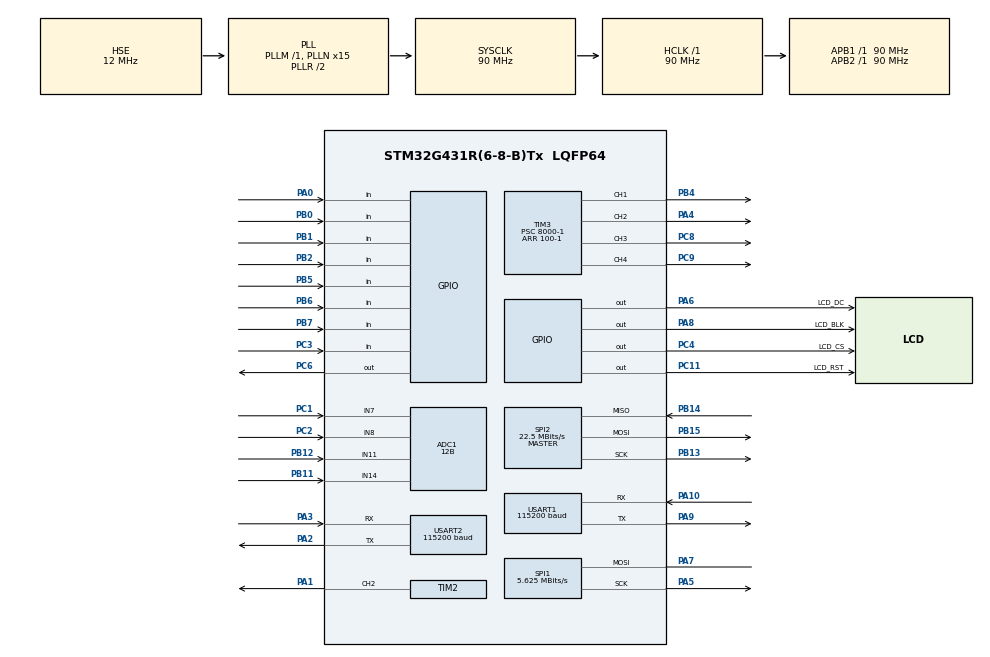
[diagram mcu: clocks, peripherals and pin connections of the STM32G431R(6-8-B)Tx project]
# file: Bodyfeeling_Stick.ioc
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ADC1.Channel-0\#ChannelRegularConversion=ADC_CHANNEL_11
ADC1.Channel-1\#ChannelRegularConversion=ADC_CHANNEL_7
ADC1.Channel-2\#ChannelRegularConversion=ADC_CHANNEL_8
ADC1.Channel-3\#ChannelRegularConversion=ADC_CHANNEL_14
ADC1.ClockPrescaler=ADC_CLOCK_ASYNC_DIV4
ADC1.ContinuousConvMode=ENABLE
ADC1.DMAContinuousRequests=ENABLE
ADC1.EOCSelection=ADC_EOC_SINGLE_CONV
ADC1.NbrOfConversion=4
ADC1.NbrOfConversionFlag=1
ADC1.OffsetNumber-0\#ChannelRegularConversion=ADC_OFFSET_NONE
ADC1.OffsetNumber-1\#ChannelRegularConversion=ADC_OFFSET_NONE
ADC1.OffsetNumber-2\#ChannelRegularConversion=ADC_OFFSET_NONE
ADC1.OffsetNumber-3\#ChannelRegularConversion=ADC_OFFSET_NONE
ADC1.Rank-0\#ChannelRegularConversion=1
ADC1.Rank-1\#ChannelRegularConversion=2
ADC1.Rank-2\#ChannelRegularConversion=3
ADC1.Rank-3\#ChannelRegularConversion=4
ADC1.Resolution=ADC_RESOLUTION_12B
ADC1.SamplingTime-0\#ChannelRegularConversion=ADC_SAMPLETIME_640CYCLES_5
ADC1.SamplingTime-1\#ChannelRegularConversion=ADC_SAMPLETIME_92CYCLES_5
ADC1.SamplingTime-2\#ChannelRegularConversion=ADC_SAMPLETIME_92CYCLES_5
ADC1.SamplingTime-3\#ChannelRegularConversion=ADC_SAMPLETIME_247CYCLES_5
ADC1.master=1
Dma.ADC1.0.Direction=DMA_PERIPH_TO_MEMORY
Dma.ADC1.0.EventEnable=DISABLE
Dma.ADC1.0.Instance=DMA1_Channel1
Dma.ADC1.0.MemDataAlignment=DMA_MDATAALIGN_HALFWORD
Dma.ADC1.0.MemInc=DMA_MINC_ENABLE
Dma.ADC1.0.Mode=DMA_CIRCULAR
Dma.ADC1.0.PeriphDataAlignment=DMA_PDATAALIGN_HALFWORD
Dma.ADC1.0.PeriphInc=DMA_PINC_DISABLE
Dma.ADC1.0.Polarity=HAL_DMAMUX_REQ_GEN_RISING
Dma.ADC1.0.Priority=DMA_PRIORITY_LOW
Dma.ADC1.0.RequestNumber=1
Dma.ADC1.0.SignalID=NONE
Dma.ADC1.0.SyncEnable=DISABLE
Dma.ADC1.0.SyncPolarity=HAL_DMAMUX_SYNC_NO_EVENT
Dma.ADC1.0.SyncRequestNumber=1
Dma.ADC1.0.SyncSignalID=NONE
Dma.Request0=ADC1
Dma.Request1=USART2_RX
Dma.Request2=USART1_TX
Dma.Request3=USART1_RX
Dma.Request4=USART2_TX
Dma.USART1_RX.3.Direction=DMA_PERIPH_TO_MEMORY
Dma.USART1_RX.3.EventEnable=DISABLE
Dma.USART1_RX.3.Instance=DMA1_Channel5
Dma.USART1_RX.3.MemDataAlignment=DMA_MDATAALIGN_BYTE
Dma.USART1_RX.3.MemInc=DMA_MINC_ENABLE
Dma.USART1_RX.3.Mode=DMA_NORMAL
Dma.USART1_RX.3.PeriphDataAlignment=DMA_PDATAALIGN_BYTE
Dma.USART1_RX.3.PeriphInc=DMA_PINC_DISABLE
Dma.USART1_RX.3.Polarity=HAL_DMAMUX_REQ_GEN_RISING
Dma.USART1_RX.3.Priority=DMA_PRIORITY_MEDIUM
Dma.USART1_RX.3.RequestNumber=1
Dma.USART1_RX.3.SignalID=NONE
Dma.USART1_RX.3.SyncEnable=DISABLE
Dma.USART1_RX.3.SyncPolarity=HAL_DMAMUX_SYNC_NO_EVENT
Dma.USART1_RX.3.SyncRequestNumber=1
Dma.USART1_RX.3.SyncSignalID=NONE
Dma.USART1_TX.2.Direction=DMA_MEMORY_TO_PERIPH
Dma.USART1_TX.2.EventEnable=DISABLE
Dma.USART1_TX.2.Instance=DMA1_Channel4
Dma.USART1_TX.2.MemDataAlignment=DMA_MDATAALIGN_BYTE
Dma.USART1_TX.2.MemInc=DMA_MINC_ENABLE
Dma.USART1_TX.2.Mode=DMA_CIRCULAR
Dma.USART1_TX.2.PeriphDataAlignment=DMA_PDATAALIGN_BYTE
Dma.USART1_TX.2.PeriphInc=DMA_PINC_DISABLE
Dma.USART1_TX.2.Polarity=HAL_DMAMUX_REQ_GEN_RISING
Dma.USART1_TX.2.Priority=DMA_PRIORITY_LOW
Dma.USART1_TX.2.RequestNumber=1
Dma.USART1_TX.2.SignalID=NONE
Dma.USART1_TX.2.SyncEnable=DISABLE
Dma.USART1_TX.2.SyncPolarity=HAL_DMAMUX_SYNC_NO_EVENT
Dma.USART1_TX.2.SyncRequestNumber=1
Dma.USART1_TX.2.SyncSignalID=NONE
Dma.USART2_RX.1.Direction=DMA_PERIPH_TO_MEMORY
Dma.USART2_RX.1.EventEnable=DISABLE
Dma.USART2_RX.1.Instance=DMA1_Channel6
Dma.USART2_RX.1.MemDataAlignment=DMA_MDATAALIGN_BYTE
Dma.USART2_RX.1.MemInc=DMA_MINC_ENABLE
Dma.USART2_RX.1.Mode=DMA_NORMAL
Dma.USART2_RX.1.PeriphDataAlignment=DMA_PDATAALIGN_BYTE
Dma.USART2_RX.1.PeriphInc=DMA_PINC_DISABLE
Dma.USART2_RX.1.Polarity=HAL_DMAMUX_REQ_GEN_RISING
Dma.USART2_RX.1.Priority=DMA_PRIORITY_MEDIUM
Dma.USART2_RX.1.RequestNumber=1
Dma.USART2_RX.1.SignalID=NONE
Dma.USART2_RX.1.SyncEnable=DISABLE
Dma.USART2_RX.1.SyncPolarity=HAL_DMAMUX_SYNC_NO_EVENT
Dma.USART2_RX.1.SyncRequestNumber=1
Dma.USART2_RX.1.SyncSignalID=NONE
Dma.USART2_TX.4.Direction=DMA_MEMORY_TO_PERIPH
Dma.USART2_TX.4.EventEnable=DISABLE
Dma.USART2_TX.4.Instance=DMA1_Channel2
Dma.USART2_TX.4.MemDataAlignment=DMA_MDATAALIGN_BYTE
Dma.USART2_TX.4.MemInc=DMA_MINC_ENABLE
Dma.USART2_TX.4.Mode=DMA_NORMAL
Dma.USART2_TX.4.PeriphDataAlignment=DMA_PDATAALIGN_BYTE
Dma.USART2_TX.4.PeriphInc=DMA_PINC_DISABLE
Dma.USART2_TX.4.Polarity=HAL_DMAMUX_REQ_GEN_RISING
Dma.USART2_TX.4.Priority=DMA_PRIORITY_LOW
Dma.USART2_TX.4.RequestNumber=1
Dma.USART2_TX.4.SignalID=NONE
Dma.USART2_TX.4.SyncEnable=DISABLE
Dma.USART2_TX.4.SyncPolarity=HAL_DMAMUX_SYNC_NO_EVENT
Dma.USART2_TX.4.SyncRequestNumber=1
Dma.USART2_TX.4.SyncSignalID=NONE
FREERTOS.BinarySemaphores01=myBinarySem01,Dynamic,NULL,Available
FREERTOS.Tasks01=defaultTask,0,128,StartDefaultTask,Default,NULL,Dynamic,NULL,NULL;LcdShow,-3,128,LcdShow_02,Default,NULL,Dynamic,NULL,NULL;Send_Rec_msg,-3,128,Send_Rec_msg_03,Default,NULL,Dynamic,NULL,NULL
Mcu.Family=STM32G4
Mcu.Name=STM32G431R(6-8-B)Tx
Mcu.Package=LQFP64
NVIC.DMA1_Channel1_IRQn=true\:5\:0\:false\:false\:true\:true\:false\:true\:true
NVIC.DMA1_Channel4_IRQn=true\:5\:0\:false\:false\:true\:false\:false\:true\:true
NVIC.DMA1_Channel5_IRQn=true\:5\:0\:false\:false\:true\:false\:false\:true\:true
NVIC.DMA1_Channel6_IRQn=true\:5\:0\:false\:false\:true\:false\:false\:true\:true
NVIC.PriorityGroup=NVIC_PRIORITYGROUP_4
NVIC.TIM6_DAC_IRQn=true\:15\:0\:false\:false\:true\:false\:false\:true\:true
NVIC.TIM7_IRQn=true\:5\:0\:false\:false\:true\:true\:true\:true\:true
NVIC.TimeBase=TIM6_DAC_IRQn
NVIC.TimeBaseIP=TIM6
NVIC.USART2_IRQn=true\:5\:0\:true\:false\:true\:true\:true\:true\:true
PA0.GPIO_Mode=GPIO_MODE_INPUT
PA0.GPIO_PuPd=GPIO_PULLUP
PA0.Signal=GPIO_Input
PA1.Signal=S_TIM2_CH2
PA10.GPIO_PuPd=GPIO_PULLDOWN
PA10.GPIO_Speed=GPIO_SPEED_FREQ_MEDIUM
PA10.Mode=Asynchronous
PA10.Signal=USART1_RX
PA13.Mode=Serial_Wire
PA13.Signal=SYS_JTMS-SWDIO
PA14.Mode=Serial_Wire
PA14.Signal=SYS_JTCK-SWCLK
PA2.Mode=Asynchronous
PA2.Signal=USART2_TX
PA3.Mode=Asynchronous
PA3.Signal=USART2_RX
PA4.Signal=S_TIM3_CH2
PA5.GPIO_PuPd=GPIO_PULLUP
PA5.GPIO_Speed=GPIO_SPEED_FREQ_HIGH
PA5.Mode=Simplex_Bidirectional_Master
PA5.Signal=SPI1_SCK
PA6.GPIO_Label=LCD_DC
PA6.Signal=GPIO_Output
PA7.GPIO_PuPd=GPIO_PULLUP
PA7.GPIO_Speed=GPIO_SPEED_FREQ_HIGH
PA7.Mode=Simplex_Bidirectional_Master
PA7.Signal=SPI1_MOSI
PA8.GPIO_Label=LCD_BLK
PA8.Signal=GPIO_Output
PA9.GPIO_PuPd=GPIO_PULLDOWN
PA9.GPIO_Speed=GPIO_SPEED_FREQ_MEDIUM
PA9.Mode=Asynchronous
PA9.Signal=USART1_TX
PB0.GPIO_Mode=GPIO_MODE_INPUT
PB0.GPIO_PuPd=GPIO_PULLUP
PB0.Signal=GPIO_Input
PB1.GPIO_Mode=GPIO_MODE_INPUT
PB1.GPIO_PuPd=GPIO_PULLUP
PB1.Signal=GPIO_Input
PB11.Signal=SharedAnalog_PB11
PB12.Signal=SharedAnalog_PB12
PB13.Mode=Full_Duplex_Master
PB13.Signal=SPI2_SCK
PB14.Mode=Full_Duplex_Master
PB14.Signal=SPI2_MISO
PB15.Mode=Full_Duplex_Master
PB15.Signal=SPI2_MOSI
PB2.GPIO_Mode=GPIO_MODE_INPUT
PB2.GPIO_PuPd=GPIO_PULLUP
PB2.Signal=GPIO_Input
PB4.Signal=S_TIM3_CH1
PB5.Signal=GPIO_Input
PB6.Signal=GPIO_Input
PB7.Signal=GPIO_Input
PC1.Signal=SharedAnalog_PC1
PC11.GPIO_Label=LCD_RST
PC11.Signal=GPIO_Output
PC2.Signal=SharedAnalog_PC2
PC3.GPIO_PuPd=GPIO_PULLUP
PC3.Signal=GPIO_Input
PC4.GPIO_Label=LCD_CS
PC4.Signal=GPIO_Output
PC6.Signal=GPIO_Output
PC8.Signal=S_TIM3_CH3
PC9.Signal=S_TIM3_CH4
PF0-OSC_IN.Mode=HSE-External-Oscillator
PF0-OSC_IN.Signal=RCC_OSC_IN
PF1-OSC_OUT.Mode=HSE-External-Oscillator
PF1-OSC_OUT.Signal=RCC_OSC_OUT
ProjectManager.HeapSize=0x200
ProjectManager.StackSize=0x400
ProjectManager.TargetToolchain=MDK-ARM V5.32
RCC.ADC12Freq_Value=90000000
RCC.AHBFreq_Value=90000000
RCC.APB1Freq_Value=90000000
RCC.APB1TimFreq_Value=90000000
RCC.APB2Freq_Value=90000000
RCC.APB2TimFreq_Value=90000000
RCC.CK48CLockSelection=RCC_USBCLKSOURCE_HSI48
RCC.CortexFreq_Value=90000000
RCC.EXTERNAL_CLOCK_VALUE=12288000
RCC.FLatency=FLASH_LATENCY_2
RCC.HCLKFreq_Value=90000000
RCC.HSE_VALUE=12000000
RCC.HSI48_VALUE=48000000
RCC.HSI_VALUE=16000000
RCC.LSE_VALUE=32768
RCC.PLLN=15
RCC.PLLSourceVirtual=RCC_PLLSOURCE_HSE
RCC.PWR_Regulator_Voltage_Scale=PWR_REGULATOR_VOLTAGE_SCALE1_BOOST
RCC.SYSCLKFreq_VALUE=90000000
RCC.SYSCLKSource=RCC_SYSCLKSOURCE_PLLCLK
RCC.USBFreq_Value=48000000
RCC.VCOOutputFreq_Value=180000000
SH.S_TIM2_CH2.0=TIM2_CH2,PWM Generation2 CH2
SH.S_TIM3_CH1.0=TIM3_CH1,PWM Generation1 CH1
SH.S_TIM3_CH2.0=TIM3_CH2,PWM Generation2 CH2
SH.S_TIM3_CH3.0=TIM3_CH3,PWM Generation3 CH3
SH.S_TIM3_CH4.0=TIM3_CH4,PWM Generation4 CH4
SH.SharedAnalog_PB11.0=GPIO_Analog
SH.SharedAnalog_PB11.1=ADC1_IN14,IN14-Single-Ended
SH.SharedAnalog_PB12.0=GPIO_Analog
SH.SharedAnalog_PB12.1=ADC1_IN11,IN11-Single-Ended
SH.SharedAnalog_PC1.0=GPIO_Analog
SH.SharedAnalog_PC1.1=ADC1_IN7,IN7-Single-Ended
SH.SharedAnalog_PC2.0=GPIO_Analog
SH.SharedAnalog_PC2.1=ADC1_IN8,IN8-Single-Ended
SPI1.BaudRatePrescaler=SPI_BAUDRATEPRESCALER_16
SPI1.CLKPhase=SPI_PHASE_2EDGE
SPI1.CLKPolarity=SPI_POLARITY_HIGH
SPI1.CRCCalculation=SPI_CRCCALCULATION_DISABLE
SPI1.CalculateBaudRate=5.625 MBits/s
SPI1.DataSize=SPI_DATASIZE_8BIT
SPI1.Direction=SPI_DIRECTION_1LINE
SPI1.FirstBit=SPI_FIRSTBIT_MSB
SPI1.Mode=SPI_MODE_MASTER
SPI1.NSS=SPI_NSS_SOFT
SPI1.TIMode=SPI_TIMODE_DISABLE
SPI1.VirtualType=VM_MASTER
SPI2.BaudRatePrescaler=SPI_BAUDRATEPRESCALER_4
SPI2.CLKPhase=SPI_PHASE_2EDGE
SPI2.CLKPolarity=SPI_POLARITY_HIGH
SPI2.CalculateBaudRate=22.5 MBits/s
SPI2.DataSize=SPI_DATASIZE_8BIT
SPI2.Direction=SPI_DIRECTION_2LINES
SPI2.Mode=SPI_MODE_MASTER
SPI2.VirtualType=VM_MASTER
TIM2.Channel-PWM\ Generation2\ CH2=TIM_CHANNEL_2
TIM3.Channel-PWM\ Generation1\ CH1=TIM_CHANNEL_1
TIM3.Channel-PWM\ Generation2\ CH2=TIM_CHANNEL_2
TIM3.Channel-PWM\ Generation3\ CH3=TIM_CHANNEL_3
TIM3.Channel-PWM\ Generation4\ CH4=TIM_CHANNEL_4
TIM3.PeriodNoDither=100-1
TIM3.Prescaler=8000-1
TIM7.PeriodNoDither=50-1
TIM7.Prescaler=9000-1
USART1.BaudRate=115200
USART1.VirtualMode-Asynchronous=VM_ASYNC
USART2.BaudRate=115200
USART2.VirtualMode-Asynchronous=VM_ASYNC
VP_FREERTOS_VS_CMSIS_V1.Mode=CMSIS_V1
VP_SYS_VS_DBSignals.Mode=DisableDeadBatterySignals
VP_SYS_VS_tim6.Mode=TIM6
VP_TIM7_VS_ClockSourceINT.Mode=Enable_Timer
board=custom

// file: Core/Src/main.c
/* USER CODE BEGIN Header */
/**
 ******************************************************************************
 * @file           : main.c
 * @brief          : Main program body
 ******************************************************************************
 * @attention
 *
 * Copyright (c) 2024 STMicroelectronics.
 * All rights reserved.
 *
 * This software is licensed under terms that can be found in the LICENSE file
 * in the root directory of this software component.
 * If no LICENSE file comes with this software, it is provided AS-IS.
 *
 ******************************************************************************
 */
/* USER CODE END Header */
#include "main.h"
#include "cmsis_os.h"
#include "adc.h"
#include "dma.h"
#include "spi.h"
#include "tim.h"
#include "usart.h"
#include "gpio.h"

/* USER CODE BEGIN Includes */
#include "HEAD.h"
/* USER CODE END Includes */

void SystemClock_Config(void);
void MX_FREERTOS_Init(void);

int main(void)
{

  /* MCU Configuration--------------------------------------------------------*/

  /* Reset of all peripherals, Initializes the Flash interface and the Systick. */
  HAL_Init();

  /* Configure the system clock */
  SystemClock_Config();

  /* Initialize all configured peripherals */
  MX_GPIO_Init();
  MX_DMA_Init();
  MX_SPI1_Init();
  MX_USART2_UART_Init();
  MX_USART1_UART_Init();
  MX_SPI2_Init();
  MX_ADC1_Init();
  MX_TIM3_Init();
  MX_TIM2_Init();
  MX_TIM7_Init();
  /* USER CODE BEGIN 2 */

    fun_init();

  /* USER CODE END 2 */

  /* Call init function for freertos objects (in cmsis_os2.c) */
  MX_FREERTOS_Init();

  /* Start scheduler */
  osKernelStart();

  /* We should never get here as control is now taken by the scheduler */

  /* Infinite loop */
    while (1)
    {

    /* USER CODE BEGIN 3 */
        fun_while();
    }
  /* USER CODE END 3 */
}

void SystemClock_Config(void)
{
  RCC_OscInitTypeDef RCC_OscInitStruct = {0};
  RCC_ClkInitTypeDef RCC_ClkInitStruct = {0};

  /** Configure the main internal regulator output voltage
  */
  HAL_PWREx_ControlVoltageScaling(PWR_REGULATOR_VOLTAGE_SCALE1_BOOST);

  /** Initializes the RCC Oscillators according to the specified parameters
  * in the RCC_OscInitTypeDef structure.
  */
  RCC_OscInitStruct.OscillatorType = RCC_OSCILLATORTYPE_HSE;
  RCC_OscInitStruct.HSEState = RCC_HSE_ON;
  RCC_OscInitStruct.PLL.PLLState = RCC_PLL_ON;
  RCC_OscInitStruct.PLL.PLLSource = RCC_PLLSOURCE_HSE;
  RCC_OscInitStruct.PLL.PLLM = RCC_PLLM_DIV1;
  RCC_OscInitStruct.PLL.PLLN = 15;
  RCC_OscInitStruct.PLL.PLLP = RCC_PLLP_DIV2;
  RCC_OscInitStruct.PLL.PLLQ = RCC_PLLQ_DIV2;
  RCC_OscInitStruct.PLL.PLLR = RCC_PLLR_DIV2;
  if (HAL_RCC_OscConfig(&RCC_OscInitStruct) != HAL_OK)
  {
    Error_Handler();
  }

  /** Initializes the CPU, AHB and APB buses clocks
  */
  RCC_ClkInitStruct.ClockType = RCC_CLOCKTYPE_HCLK|RCC_CLOCKTYPE_SYSCLK
                              |RCC_CLOCKTYPE_PCLK1|RCC_CLOCKTYPE_PCLK2;
  RCC_ClkInitStruct.SYSCLKSource = RCC_SYSCLKSOURCE_PLLCLK;
  RCC_ClkInitStruct.AHBCLKDivider = RCC_SYSCLK_DIV1;
  RCC_ClkInitStruct.APB1CLKDivider = RCC_HCLK_DIV1;
  RCC_ClkInitStruct.APB2CLKDivider = RCC_HCLK_DIV1;

  if (HAL_RCC_ClockConfig(&RCC_ClkInitStruct, FLASH_LATENCY_2) != HAL_OK)
  {
    Error_Handler();
  }
}

void HAL_TIM_PeriodElapsedCallback(TIM_HandleTypeDef *htim)
{
  if (htim->Instance == TIM6) {
    HAL_IncTick();
  }
}

void Error_Handler(void)
{
    __disable_irq();
    while (1)
    {
    }
}

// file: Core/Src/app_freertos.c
/* USER CODE BEGIN Header */
/**
 ******************************************************************************
 * File Name          : app_freertos.c
 * Description        : Code for freertos applications
 ******************************************************************************
 * @attention
 *
 * Copyright (c) 2025 STMicroelectronics.
 * All rights reserved.
 *
 * This software is licensed under terms that can be found in the LICENSE file
 * in the root directory of this software component.
 * If no LICENSE file comes with this software, it is provided AS-IS.
 *
 ******************************************************************************
 */
/* USER CODE END Header */

#include "FreeRTOS.h"
#include "task.h"
#include "main.h"
#include "cmsis_os.h"

/* USER CODE BEGIN Includes */
#include "head.h"
/* USER CODE END Includes */

osThreadId defaultTaskHandle;
osThreadId LcdShowHandle;
osThreadId Send_Rec_msgHandle;
osSemaphoreId myBinarySem01Handle;

void StartDefaultTask(void const * argument);
void LcdShow_02(void const * argument);
void Send_Rec_msg_03(void const * argument);

void MX_FREERTOS_Init(void); /* (MISRA C 2004 rule 8.1) */

void MX_FREERTOS_Init(void) {

  /* Create the semaphores(s) */
  /* definition and creation of myBinarySem01 */
  osSemaphoreDef(myBinarySem01);
  myBinarySem01Handle = osSemaphoreCreate(osSemaphore(myBinarySem01), 1);

  /* Create the thread(s) */
  /* definition and creation of defaultTask */
  osThreadDef(defaultTask, StartDefaultTask, osPriorityNormal, 0, 128);
  defaultTaskHandle = osThreadCreate(osThread(defaultTask), NULL);

  /* definition and creation of LcdShow */
  osThreadDef(LcdShow, LcdShow_02, osPriorityIdle, 0, 128);
  LcdShowHandle = osThreadCreate(osThread(LcdShow), NULL);

  /* definition and creation of Send_Rec_msg */
  osThreadDef(Send_Rec_msg, Send_Rec_msg_03, osPriorityIdle, 0, 128);
  Send_Rec_msgHandle = osThreadCreate(osThread(Send_Rec_msg), NULL);

}

void StartDefaultTask(void const * argument)
{
  /* USER CODE BEGIN StartDefaultTask */
    /* Infinite loop */
    for (;;)
    {
        osDelay(1);
        key_scan();
    }
  /* USER CODE END StartDefaultTask */
}

void LcdShow_02(void const * argument)
{
  /* USER CODE BEGIN LcdShow_02 */
    /* Infinite loop */
    for (;;)
    {
        osDelay(1);
        lcd_disp();

    }
  /* USER CODE END LcdShow_02 */
}

void Send_Rec_msg_03(void const * argument)
{
  /* USER CODE BEGIN Send_Rec_msg_03 */

    /* Infinite loop */
    for (;;)
    {
      imu_prog();
      send_order();
      osDelay(35); // 延时10ms
    }
  /* USER CODE END Send_Rec_msg_03 */
}
